# DA14682 register map
Vendor: Dialog; Series: DA14682; File version: 1.2
CPU: CM0 r1p0, little endian, MPU, FPU, 3 interrupt priority bits
Registers are 16-bit, read-write, reset 0x0 unless marked. A register's access mark holds for its fields unless they carry their own. Offsets are from the block's base; [hi:lo] are bit positions.

## ECC — ECC registers
Base 0x50006000
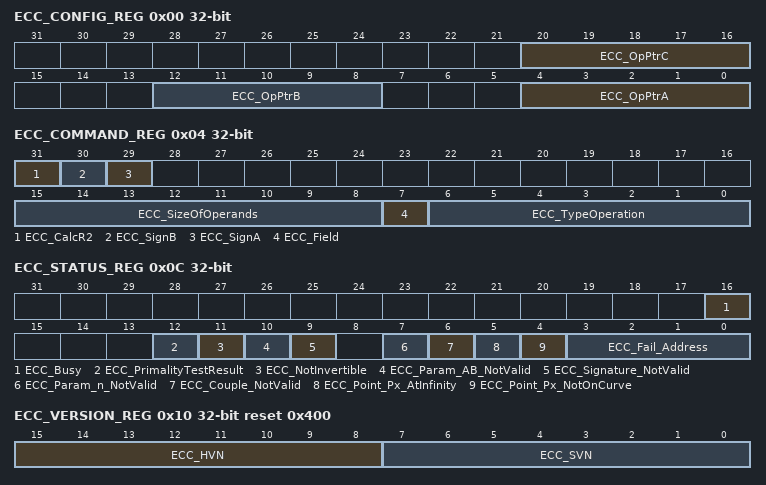
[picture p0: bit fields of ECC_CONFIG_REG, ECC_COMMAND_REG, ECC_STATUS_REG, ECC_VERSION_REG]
0x00 ECC_CONFIG_REG 32-bit — Configuration register
  [20:16] ECC_OpPtrC — When executing primitive arithmetic operations, this pointer defines the location where the result will be stored in Memory.
  [12:8] ECC_OpPtrB — When executing primitive arithmetic operations, this Pointer defines where operand B is located in memory.
  [4:0] ECC_OpPtrA — When executing primitive arithmetic operations, this Pointer defines where operand A is located in memory.
0x04 ECC_COMMAND_REG 32-bit (reset mask 0x7FFFFFFF) — Command register
  [31] ECC_CalcR2 — This bit indicates if the IP has to calculate R mod N for the next operation. This bit must be set to 1 when a new prime number has been programmed. This bit is automatically cleared when R mod N has been calculated. '0': no effect '1': forces the IP to re-calculate R mod N
  [30] ECC_SignB — Sign of parameter B in equation y2=x3+Ax+B '0': B is positive '1': B is negative
  [29] ECC_SignA — Sign of parameter A in equation y2=x3+Ax+B '0': A is positive '1': A is negative
  [15:8] ECC_SizeOfOperands — This field defines the size (= number of 64-bit double words) of the operands for the current operation. Possible values are limited by the generic parameter g_Log2MaxDataSize that defines the max space allocated or reserved to each operand. Arbitrary Data/Key size from 128 up to 2566 are supported: 0x02 (02d) -> 128-bit Data/Key size 0x03 (02d) -> 256-bit Data/Key size ECC-ECDSA - Prime Field F(p) 0x03 -> 192-bit (Curve P-192) 0x04 -> 256-bit (Curves P-224 & P-256) ECC-ECDSA - Binary Field F(2m) 0x03 -> 192-bit (Curve K-163) 0x04 -> 256-bit (Curve K-233) - 4 Xers: 0x01, 0x02, 0x4, 0x6 -> 64, 128 & multiples of 128 bits
  [7] ECC_Field — '0': Field is F(p) '1': Field is F(2m)
  [6:0] ECC_TypeOperation — Primitive Arithmetic Operations F(p) & F(2m) [6:4] = 0x0 [3:0] = 0x0 -> Reserved 0x1 -> Modular Addition 0x2 -> Modular Subtraction 0x3 -> Modular Multiplication (Odd N) 0x4 -> Modular Reduction (Odd N) 0x5 -> Modular Division (Odd N) 0x6 -> Modular Inversion (Odd N) 0x7 -> Reserved 0x8 -> Multiplication 0x9 -> Modular Inversion (Even N) 0xA -> Modular Reduction (Even N) others -> Reserved C = A + B mod N C = A - B mod N C = A * B mod N C = B mod N C = A/B mod N C = 1/B mod N C = A * B C = 1/B mod N C = B mod N High-level RSA, CRT & DSA Operations - F(p) only ([7] forced to 0) [6:4] = 0x1 [3:0] = 0x0 -> MulModN 0x1 -> MulAddN 0x2 -> ECMQV (part1) others -> Reserved Primitive ECC & Check Point Operations F(p) & F(2m) [6:4] = 0x2 [3:0] = 0x0 -> Point Doubling (Projective Coord.) 0x1 -> ptAdd3 0x2 -> GenSessionKey 0x3 -> Check_AB (ECDSA) 0x4 -> Check_n (ECDSA) 0x5 -> Check single value less than N 0x6 -> Check_Point_On_Curve 0x7-> Reserved 0x8 -> Curve25519 point multiplication 0x9 -> Ed25519 Check point on curve 0xA -> Ed25519 ScalarMult 0xB -> Ed25519 CheckValid others -> Reserved High-level ECC ECDSA Operations F(p) & F(2m) [6:4] = 0x3 [3:0] = 0x0 -> ECMQV (part 2) 0x1 -> Verify ZKP 0x2 -> ECDSA Domain Parameters Validation others -> Reserved [6:4]=0x4, 0x5, 0x6, 0x7 -> Reserved
0x08 ECC_CONTROL_REG 32-bit — Control register
  [0] ECC_Start — The Start signal is activated when all data and key inputs have been loaded in the external crypto memory and are available for processing. This signal is active high and is sampled on the rising edge of Clk. When this signal goes high, the PK Command present in the PK_CommandReg[] is initiated and executed. The PK_Start signal is ignored when the core is already processing data and is automatically cleared when the operation is finished
0x0C ECC_STATUS_REG 32-bit — Status register
  [16] ECC_Busy ro — This Status Signal indicates that the core is processing data. This signal is active high and goes low when the selected algorithm is finished.
  [12] ECC_PrimalityTestResult ro — After the Miller-Rabin Primality test, this flag is: - set to 0 when the random number under test is probably prime - cleared to 1 when the random number under test is composite
  [11] ECC_NotInvertible ro — This flag is set to 1 when executing a modular inversion (PK_CommandReg[3:0] = 0x6 or 0x9) if the operand is not invertible.
  [10] ECC_Param_AB_NotValid ro — Status signal set to 1 when parameters A and B are not valid, i.e 4A+ 27B = 0. This flag is updated after execution of the command Check_AB.
  [9] ECC_Signature_NotValid ro — This flag indicates if the signature can be accepted or must be rejected. This flag is set to 1 when the signature is not valid and is updated after execution of the command ECDSA_Generation, ECDSA_Verification, DSA_Generation, DSA_Verification.
  [7] ECC_Param_n_NotValid ro — Status signal set to 1 when Parameter n is not valid. This flag is updated after execution of the command Check_n.
  [6] ECC_Couple_NotValid ro — Status signal set to 1 when couple x, y is not valid (i.e. not smaller than the prime). This flag is updated after execution of the command Check_Couple_Less_Prime.
  [5] ECC_Point_Px_AtInfinity ro — Status signal set to 1 when Point Px is at the infinity. This flag is updated after execution of an ECC operation.
  [4] ECC_Point_Px_NotOnCurve ro — Status signal set to 1 when Point Px is not on the defined EC. This flag is updated after execution of the command Check_Point_OnCurve.
  [3:0] ECC_Fail_Address ro — Address of the last Point detected as Not On Curve, Not Valid or at the infinity.
0x10 ECC_VERSION_REG 32-bit reset 0x400 — Version register
  [15:8] ECC_HVN ro — Version of IP to be read via CPU interface.
  [7:0] ECC_SVN ro — Version of Crypto code to be read via CPU interface.Note that this should be read before ECC is used since it corrupts its contents.
